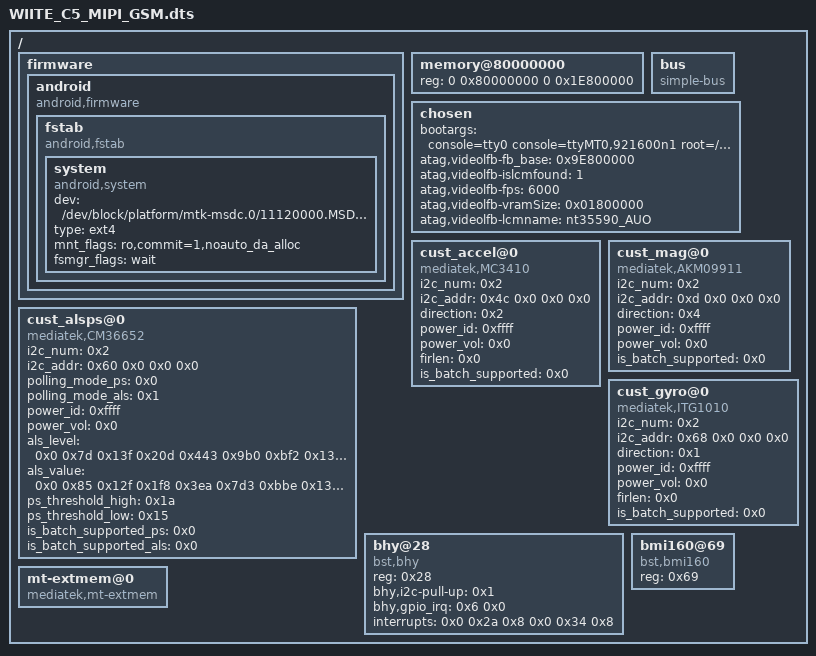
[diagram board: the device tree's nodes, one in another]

/dts-v1/;

/include/ "kw06.dtsi"
/include/ "cust_eint_kw06.dtsi"

/ {

	firmware {
		android {
			compatible = "android,firmware";
			fstab {
				compatible = "android,fstab";
				system {
					compatible = "android,system";
					dev = "/dev/block/platform/mtk-msdc.0/11120000.MSDC0/by-name/system";
					type = "ext4";
					mnt_flags = "ro,commit=1,noauto_da_alloc";
					fsmgr_flags = "wait";
				};
			};
		};
	};

	memory@80000000 {
		device_type = "memory";
		reg = <0 0x80000000 0 0x1E800000>;
	};

	bus {
		compatible = "simple-bus";
		#address-cells = <1>;
		#size-cells = <1>;
		ranges = <0 0 0 0xffffffff>;
	};

    /* chosen */
    chosen {
        bootargs = "console=tty0 console=ttyMT0,921600n1 root=/dev/ram initrd=0x84000000,0x400000 loglevel=8";
		/* fpga may has no lk, we need to specify display info here */
		/* fb buffer is reserved using this dts by memory node above */
		atag,videolfb-fb_base = <0x9E800000>;
		atag,videolfb-islcmfound = <1>;
		atag,videolfb-fps= <6000>;
		atag,videolfb-vramSize= <0x01800000>;
		atag,videolfb-lcmname= "nt35590_AUO";
    };
  /*  start sensor */
		cust_accel@0 {
		compatible 				= "mediatek,MC3410";
		i2c_num 				= <2>;
		i2c_addr				= <0x4c 0 0 0>;
		direction 				= <2>;
		power_id 				= <0xffff>;
		power_vol				= <0>;
		firlen 					= <0>;
		is_batch_supported  			= <0>;
  		};
  
		cust_alsps@0 {
		compatible 				= "mediatek,CM36652";
		i2c_num 				= <2>;
		i2c_addr 				= <0x60 0 0 0>;
		polling_mode_ps			= <0>;
		polling_mode_als		= <1>;
		power_id   				= <0xffff>;
		power_vol  				= <0>; 
/* Total has 15 level*/
		als_level  				= <0 125 319 525 1091 2480 3058 5115 8589 10769 12857 17807 22091 65535 65535>;
/*  Total has 16 range*/
		als_value  				= <0 133 303 504 1002 2003 3006 5003 8002 10000 12000 16000 20000 20000 20000 20000>;
		ps_threshold_high		=  <26>;
		ps_threshold_low		=  <21>;
		is_batch_supported_ps	= <0>;
		is_batch_supported_als	= <0>;
		};
		
  		cust_mag@0 {
		compatible				= "mediatek,AKM09911";
		i2c_num 				= <2>;
		i2c_addr				= <0x0D 0 0 0>;
		direction 				= <4>;
		power_id 				= <0xffff>;
		power_vol				= <0>;
		is_batch_supported  	= <0>;
  		};
		
  		cust_gyro@0 {
		compatible 				= "mediatek,ITG1010";
		i2c_num 				= <2>;
		i2c_addr				= <0x68 0 0 0>;
		direction 				= <1>;
		power_id 				= <0xffff>;
		power_vol				= <0>;
		firlen 					= <0>;
		is_batch_supported  	= <0>;
  		};

	cust_accel@0 {
		compatible = "mediatek,MC3410";
		i2c_num = <0x2>;
		i2c_addr = <0x4c 0x0 0x0 0x0>;
		direction = <0x2>;
		power_id = <0xffff>;
		power_vol = <0x0>;
		firlen = <0x0>;
		is_batch_supported = <0x0>;
	};

		cust_alsps@0 {
			compatible = "mediatek,CM36652";
			i2c_num = <0x2>;
			i2c_addr = <0x60 0x0 0x0 0x0>;
			polling_mode_ps = <0x0>;
			polling_mode_als = <0x1>;
			power_id = <0xffff>;
			power_vol = <0x0>;
			als_level = <0x0 0x7d 0x13f 0x20d 0x443 0x9b0 0xbf2 0x13fb 0x218d 0x2a11 0x3239 0x458f 0x564b 0xffff 0xffff>;
			als_value = <0x0 0x85 0x12f 0x1f8 0x3ea 0x7d3 0xbbe 0x138b 0x1f42 0x2710 0x2ee0 0x3e80 0x4e20 0x4e20 0x4e20 0x4e20>;
			ps_threshold_high = <0x1a>;
			ps_threshold_low = <0x15>;
			is_batch_supported_ps = <0x0>;
			is_batch_supported_als = <0x0>;
		};

		cust_mag@0 {
			compatible = "mediatek,AKM09911";
			i2c_num = <0x2>;
			i2c_addr = <0xd 0x0 0x0 0x0>;
			direction = <0x4>;
			power_id = <0xffff>;
			power_vol = <0x0>;
			is_batch_supported = <0x0>;
		};

		cust_gyro@0 {
			compatible = "mediatek,ITG1010";
			i2c_num = <0x2>;
			i2c_addr = <0x68 0x0 0x0 0x0>;
			direction = <0x1>;
			power_id = <0xffff>;
			power_vol = <0x0>;
			firlen = <0x0>;
			is_batch_supported = <0x0>;
		};

		bhy@28 {
			compatible = "bst,bhy";
			reg = <0x28>;
			bhy,i2c-pull-up = <0x1>;
			bhy,gpio_irq = <0x6 0x0>;
			interrupts = <0x0 0x2a 0x8 0x0 0x34 0x8>;
		};

		bmi160@69 {
			compatible = "bst,bmi160";
			reg = <0x69>;
		};

  /* end sensor */

	mt-extmem@0 {
		compatible = "mediatek,mt-extmem";
	};	
};
